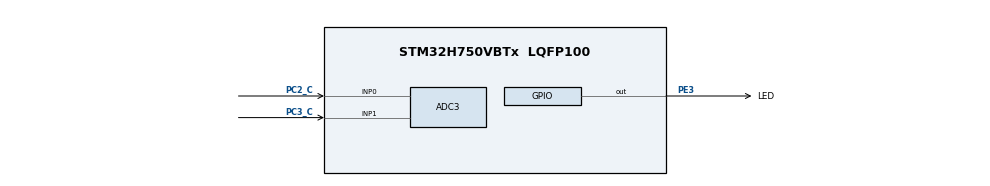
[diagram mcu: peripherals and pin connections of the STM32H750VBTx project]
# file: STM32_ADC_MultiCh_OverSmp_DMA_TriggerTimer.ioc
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ADC3.Channel-0\#ChannelRegularConversion=ADC_CHANNEL_VREFINT
ADC3.Channel-1\#ChannelRegularConversion=ADC_CHANNEL_0
ADC3.Channel-2\#ChannelRegularConversion=ADC_CHANNEL_1
ADC3.ContinuousConvMode=DISABLE
ADC3.ConversionDataManagement=ADC_CONVERSIONDATA_DMA_CIRCULAR
ADC3.EOCSelection=ADC_EOC_SEQ_CONV
ADC3.ExternalTrigConv=ADC_EXTERNALTRIG_T6_TRGO
ADC3.NbrOfConversion=3
ADC3.NbrOfConversionFlag=1
ADC3.OffsetNumber-0\#ChannelRegularConversion=ADC_OFFSET_NONE
ADC3.OffsetNumber-1\#ChannelRegularConversion=ADC_OFFSET_NONE
ADC3.OffsetNumber-2\#ChannelRegularConversion=ADC_OFFSET_NONE
ADC3.OffsetSignedSaturation-0\#ChannelRegularConversion=DISABLE
ADC3.OffsetSignedSaturation-1\#ChannelRegularConversion=DISABLE
ADC3.OffsetSignedSaturation-2\#ChannelRegularConversion=DISABLE
ADC3.Overrun=ADC_OVR_DATA_PRESERVED
ADC3.OversamplingMode=ENABLE
ADC3.Rank-0\#ChannelRegularConversion=1
ADC3.Rank-1\#ChannelRegularConversion=2
ADC3.Rank-2\#ChannelRegularConversion=3
ADC3.Ratio=1024
ADC3.RightBitShift=ADC_RIGHTBITSHIFT_10
ADC3.SamplingTime-0\#ChannelRegularConversion=ADC_SAMPLETIME_8CYCLES_5
ADC3.SamplingTime-1\#ChannelRegularConversion=ADC_SAMPLETIME_8CYCLES_5
ADC3.SamplingTime-2\#ChannelRegularConversion=ADC_SAMPLETIME_8CYCLES_5
CORTEX_M7.CPU_DCache=Enabled
CORTEX_M7.CPU_ICache=Enabled
Dma.ADC3.0.Direction=DMA_PERIPH_TO_MEMORY
Dma.ADC3.0.EventEnable=DISABLE
Dma.ADC3.0.FIFOMode=DMA_FIFOMODE_DISABLE
Dma.ADC3.0.Instance=DMA1_Stream0
Dma.ADC3.0.MemDataAlignment=DMA_MDATAALIGN_HALFWORD
Dma.ADC3.0.MemInc=DMA_MINC_ENABLE
Dma.ADC3.0.Mode=DMA_CIRCULAR
Dma.ADC3.0.PeriphDataAlignment=DMA_PDATAALIGN_HALFWORD
Dma.ADC3.0.PeriphInc=DMA_PINC_DISABLE
Dma.ADC3.0.Polarity=HAL_DMAMUX_REQ_GEN_RISING
Dma.ADC3.0.Priority=DMA_PRIORITY_LOW
Dma.ADC3.0.RequestNumber=1
Dma.ADC3.0.SignalID=NONE
Dma.ADC3.0.SyncEnable=DISABLE
Dma.ADC3.0.SyncPolarity=HAL_DMAMUX_SYNC_NO_EVENT
Dma.ADC3.0.SyncRequestNumber=1
Dma.ADC3.0.SyncSignalID=NONE
Dma.Request0=ADC3
Mcu.Family=STM32H7
Mcu.Name=STM32H750VBTx
Mcu.Package=LQFP100
NVIC.DMA1_Stream0_IRQn=true\:0\:0\:false\:false\:true\:false\:true
NVIC.PriorityGroup=NVIC_PRIORITYGROUP_4
PC2_C.Mode=IN0-Single-Ended
PC2_C.Signal=ADC3_INP0
PC3_C.Mode=IN1-Single-Ended
PC3_C.Signal=ADC3_INP1
PE3.GPIO_Label=LED
PE3.Signal=GPIO_Output
ProjectManager.HeapSize=0x200
ProjectManager.StackSize=0x400
ProjectManager.TargetToolchain=STM32CubeIDE
RCC.ADCFreq_Value=37500000
RCC.APB1Freq_Value=120000000
RCC.APB2Freq_Value=120000000
RCC.APB3Freq_Value=120000000
RCC.APB4Freq_Value=120000000
RCC.CortexFreq_Value=240000000
RCC.DIVM1=4
RCC.DIVM2=4
RCC.DIVN1=30
RCC.DIVN2=9
RCC.DIVP2=4
RCC.HCLKFreq_Value=120000000
RCC.HPRE=RCC_HCLK_DIV2
RCC.PLL2FRACN=3072
RCC.PLL3FRACN=0
RCC.PLLFRACN=0
RCC.PWR_Regulator_Voltage_Scale=PWR_REGULATOR_VOLTAGE_SCALE2
RCC.ProductRev=revV
RCC.SYSCLKFreq_VALUE=240000000
RCC.SYSCLKSource=RCC_SYSCLKSOURCE_PLLCLK
RCC.USBFreq_Value=240000000
TIM6.AutoReloadPreload=TIM_AUTORELOAD_PRELOAD_DISABLE
TIM6.Period=9999
TIM6.Prescaler=11999
TIM6.TIM_MasterOutputTrigger=TIM_TRGO_UPDATE
VP_ADC3_Vref_Input.Mode=IN-Vrefint
VP_TIM6_VS_ClockSourceINT.Mode=Enable_Timer
board=custom

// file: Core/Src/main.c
/* USER CODE BEGIN Header */
/**
  ******************************************************************************
  * @file           : main.c
  * @brief          : Main program body
  ******************************************************************************
  * @attention
  *
  * <h2><center>&copy; Copyright (c) 2021 STMicroelectronics.
  * All rights reserved.</center></h2>
  *
  * This software component is licensed by ST under BSD 3-Clause license,
  * the "License"; You may not use this file except in compliance with the
  * License. You may obtain a copy of the License at:
  *                        opensource.org/licenses/BSD-3-Clause
  *
  ******************************************************************************
  */
/* USER CODE END Header */
#include "main.h"

/* USER CODE BEGIN PD */
#define ChannelNo	3
/* USER CODE END PD */

ADC_HandleTypeDef hadc3;
DMA_HandleTypeDef hdma_adc3;

TIM_HandleTypeDef htim6;

/* USER CODE BEGIN PV */
uint16_t DMABuf[ChannelNo];
uint16_t VRefInt, ADC_INP0, ADC_INP1;
uint8_t DMA_Cplt = 0;
/* USER CODE END PV */

void SystemClock_Config(void);
static void MX_GPIO_Init(void);
static void MX_ADC3_Init(void);
static void MX_DMA_Init(void);
static void MX_TIM6_Init(void);

int main(void)
{

  /* Enable I-Cache---------------------------------------------------------*/
  SCB_EnableICache();

  /* Enable D-Cache---------------------------------------------------------*/
  SCB_EnableDCache();

  /* MCU Configuration--------------------------------------------------------*/

  /* Reset of all peripherals, Initializes the Flash interface and the Systick. */
  HAL_Init();

  /* Configure the system clock */
  SystemClock_Config();

  /* Initialize all configured peripherals */
  MX_GPIO_Init();
  MX_ADC3_Init();
  MX_DMA_Init();
  MX_TIM6_Init();
  /* USER CODE BEGIN 2 */
#ifdef LL_Driver
  LL_ADC_SetCommonPathInternalCh(__LL_ADC_COMMON_INSTANCE(ADC3),
		  LL_ADC_PATH_INTERNAL_VREFINT);
  LL_ADC_SetChannelPreSelection(ADC3, LL_ADC_CHANNEL_VREFINT);
  LL_ADC_SetChannelPreSelection(ADC3, LL_ADC_CHANNEL_0);
  LL_ADC_SetChannelPreSelection(ADC3, LL_ADC_CHANNEL_1);
  LL_ADC_REG_SetDataTransferMode(ADC3, LL_ADC_REG_DMA_TRANSFER_UNLIMITED);

  LL_ADC_StartCalibration(ADC3, LL_ADC_CALIB_OFFSET, LL_ADC_SINGLE_ENDED);
  while( LL_ADC_IsCalibrationOnGoing(ADC3));

  LL_TIM_EnableCounter(TIM6);

  LL_DMA_ConfigAddresses(DMA1, LL_DMA_STREAM_0,
		  LL_ADC_DMA_GetRegAddr(ADC3, LL_ADC_DMA_REG_REGULAR_DATA),
		  (uint32_t)&DMABuf, LL_DMA_DIRECTION_PERIPH_TO_MEMORY);
  LL_DMA_SetDataLength(DMA1, LL_DMA_STREAM_0, ChannelNo);
  LL_DMA_EnableIT_TC(DMA1, LL_DMA_STREAM_0);
  LL_DMA_EnableStream(DMA1, LL_DMA_STREAM_0);

  LL_ADC_Enable(ADC3);
  while(LL_ADC_IsActiveFlag_ADRDY(ADC3) != SET);
  LL_ADC_REG_StartConversion(ADC3);
#else
  if (HAL_ADCEx_Calibration_Start(&hadc3, ADC_CALIB_OFFSET, ADC_SINGLE_ENDED)
		  != HAL_OK)
  {
	  return HAL_ERROR;
  }

  if (HAL_TIM_Base_Start(&htim6) != HAL_OK)
  {
	  return HAL_ERROR;
  }

  if (HAL_ADC_Start_DMA(&hadc3, (uint32_t*)DMABuf, ChannelNo) != HAL_OK)
  {
	  return HAL_ERROR;
  }
#endif
  /* USER CODE END 2 */

  /* Infinite loop */
  while (1)
  {

    /* USER CODE BEGIN 3 */
	  if (DMA_Cplt == 1)
	  {
#ifdef LL_Driver
		  VRefInt	= __LL_ADC_CALC_VREFANALOG_VOLTAGE(DMABuf[0],
				  LL_ADC_GetResolution(ADC3));
		  ADC_INP0 	= __LL_ADC_CALC_DATA_TO_VOLTAGE(VRefInt, DMABuf[1],
				  LL_ADC_GetResolution(ADC3));
		  ADC_INP1 	= __LL_ADC_CALC_DATA_TO_VOLTAGE(VRefInt, DMABuf[2],
				  LL_ADC_GetResolution(ADC3));
#else
		  VRefInt	= __HAL_ADC_CALC_VREFANALOG_VOLTAGE(DMABuf[0],
				  hadc3.Init.Resolution);
		  ADC_INP0 	= __HAL_ADC_CALC_DATA_TO_VOLTAGE(VRefInt, DMABuf[1],
				  hadc3.Init.Resolution);
		  ADC_INP1 	= __HAL_ADC_CALC_DATA_TO_VOLTAGE(VRefInt, DMABuf[2],
				  hadc3.Init.Resolution);
#endif
		  DMA_Cplt	= 0;
	  }
  }
  /* USER CODE END 3 */
}

void SystemClock_Config(void)
{
  RCC_OscInitTypeDef RCC_OscInitStruct = {0};
  RCC_ClkInitTypeDef RCC_ClkInitStruct = {0};

  /** Supply configuration update enable
  */
  HAL_PWREx_ConfigSupply(PWR_LDO_SUPPLY);
  /** Configure the main internal regulator output voltage
  */
  __HAL_PWR_VOLTAGESCALING_CONFIG(PWR_REGULATOR_VOLTAGE_SCALE2);

  while(!__HAL_PWR_GET_FLAG(PWR_FLAG_VOSRDY)) {}
  /** Macro to configure the PLL clock source
  */
  __HAL_RCC_PLL_PLLSOURCE_CONFIG(RCC_PLLSOURCE_HSI);
  /** Initializes the RCC Oscillators according to the specified parameters
  * in the RCC_OscInitTypeDef structure.
  */
  RCC_OscInitStruct.OscillatorType = RCC_OSCILLATORTYPE_HSI;
  RCC_OscInitStruct.HSIState = RCC_HSI_DIV1;
  RCC_OscInitStruct.HSICalibrationValue = RCC_HSICALIBRATION_DEFAULT;
  RCC_OscInitStruct.PLL.PLLState = RCC_PLL_ON;
  RCC_OscInitStruct.PLL.PLLSource = RCC_PLLSOURCE_HSI;
  RCC_OscInitStruct.PLL.PLLM = 4;
  RCC_OscInitStruct.PLL.PLLN = 30;
  RCC_OscInitStruct.PLL.PLLP = 2;
  RCC_OscInitStruct.PLL.PLLQ = 2;
  RCC_OscInitStruct.PLL.PLLR = 2;
  RCC_OscInitStruct.PLL.PLLRGE = RCC_PLL1VCIRANGE_3;
  RCC_OscInitStruct.PLL.PLLVCOSEL = RCC_PLL1VCOWIDE;
  RCC_OscInitStruct.PLL.PLLFRACN = 0;
  if (HAL_RCC_OscConfig(&RCC_OscInitStruct) != HAL_OK)
  {
    Error_Handler();
  }
  /** Initializes the CPU, AHB and APB buses clocks
  */
  RCC_ClkInitStruct.ClockType = RCC_CLOCKTYPE_HCLK|RCC_CLOCKTYPE_SYSCLK
                              |RCC_CLOCKTYPE_PCLK1|RCC_CLOCKTYPE_PCLK2
                              |RCC_CLOCKTYPE_D3PCLK1|RCC_CLOCKTYPE_D1PCLK1;
  RCC_ClkInitStruct.SYSCLKSource = RCC_SYSCLKSOURCE_PLLCLK;
  RCC_ClkInitStruct.SYSCLKDivider = RCC_SYSCLK_DIV1;
  RCC_ClkInitStruct.AHBCLKDivider = RCC_HCLK_DIV2;
  RCC_ClkInitStruct.APB3CLKDivider = RCC_APB3_DIV1;
  RCC_ClkInitStruct.APB1CLKDivider = RCC_APB1_DIV1;
  RCC_ClkInitStruct.APB2CLKDivider = RCC_APB2_DIV1;
  RCC_ClkInitStruct.APB4CLKDivider = RCC_APB4_DIV1;

  if (HAL_RCC_ClockConfig(&RCC_ClkInitStruct, FLASH_LATENCY_2) != HAL_OK)
  {
    Error_Handler();
  }
}

static void MX_ADC3_Init(void)
{

  ADC_ChannelConfTypeDef sConfig = {0};

  /** Common config
  */
  hadc3.Instance = ADC3;
  hadc3.Init.ClockPrescaler = ADC_CLOCK_ASYNC_DIV2;
  hadc3.Init.Resolution = ADC_RESOLUTION_16B;
  hadc3.Init.ScanConvMode = ADC_SCAN_ENABLE;
  hadc3.Init.EOCSelection = ADC_EOC_SEQ_CONV;
  hadc3.Init.LowPowerAutoWait = DISABLE;
  hadc3.Init.ContinuousConvMode = DISABLE;
  hadc3.Init.NbrOfConversion = 3;
  hadc3.Init.DiscontinuousConvMode = DISABLE;
  hadc3.Init.ExternalTrigConv = ADC_EXTERNALTRIG_T6_TRGO;
  hadc3.Init.ExternalTrigConvEdge = ADC_EXTERNALTRIGCONVEDGE_RISING;
  hadc3.Init.ConversionDataManagement = ADC_CONVERSIONDATA_DMA_CIRCULAR;
  hadc3.Init.Overrun = ADC_OVR_DATA_PRESERVED;
  hadc3.Init.LeftBitShift = ADC_LEFTBITSHIFT_NONE;
  hadc3.Init.OversamplingMode = ENABLE;
  hadc3.Init.Oversampling.Ratio = 1024;
  hadc3.Init.Oversampling.RightBitShift = ADC_RIGHTBITSHIFT_10;
  hadc3.Init.Oversampling.TriggeredMode = ADC_TRIGGEREDMODE_SINGLE_TRIGGER;
  hadc3.Init.Oversampling.OversamplingStopReset = ADC_REGOVERSAMPLING_CONTINUED_MODE;
  if (HAL_ADC_Init(&hadc3) != HAL_OK)
  {
    Error_Handler();
  }
  /** Configure Regular Channel
  */
  sConfig.Channel = ADC_CHANNEL_VREFINT;
  sConfig.Rank = ADC_REGULAR_RANK_1;
  sConfig.SamplingTime = ADC_SAMPLETIME_8CYCLES_5;
  sConfig.SingleDiff = ADC_SINGLE_ENDED;
  sConfig.OffsetNumber = ADC_OFFSET_NONE;
  sConfig.Offset = 0;
  sConfig.OffsetSignedSaturation = DISABLE;
  if (HAL_ADC_ConfigChannel(&hadc3, &sConfig) != HAL_OK)
  {
    Error_Handler();
  }
  /** Configure Regular Channel
  */
  sConfig.Channel = ADC_CHANNEL_0;
  sConfig.Rank = ADC_REGULAR_RANK_2;
  if (HAL_ADC_ConfigChannel(&hadc3, &sConfig) != HAL_OK)
  {
    Error_Handler();
  }
  /** Configure Regular Channel
  */
  sConfig.Channel = ADC_CHANNEL_1;
  sConfig.Rank = ADC_REGULAR_RANK_3;
  if (HAL_ADC_ConfigChannel(&hadc3, &sConfig) != HAL_OK)
  {
    Error_Handler();
  }

}

static void MX_TIM6_Init(void)
{

  TIM_MasterConfigTypeDef sMasterConfig = {0};

  htim6.Instance = TIM6;
  htim6.Init.Prescaler = 11999;
  htim6.Init.CounterMode = TIM_COUNTERMODE_UP;
  htim6.Init.Period = 9999;
  htim6.Init.AutoReloadPreload = TIM_AUTORELOAD_PRELOAD_DISABLE;
  if (HAL_TIM_Base_Init(&htim6) != HAL_OK)
  {
    Error_Handler();
  }
  sMasterConfig.MasterOutputTrigger = TIM_TRGO_UPDATE;
  sMasterConfig.MasterSlaveMode = TIM_MASTERSLAVEMODE_DISABLE;
  if (HAL_TIMEx_MasterConfigSynchronization(&htim6, &sMasterConfig) != HAL_OK)
  {
    Error_Handler();
  }

}

static void MX_DMA_Init(void)
{

  /* DMA controller clock enable */
  __HAL_RCC_DMA1_CLK_ENABLE();

  /* DMA interrupt init */
  /* DMA1_Stream0_IRQn interrupt configuration */
  HAL_NVIC_SetPriority(DMA1_Stream0_IRQn, 0, 0);
  HAL_NVIC_EnableIRQ(DMA1_Stream0_IRQn);

}

static void MX_GPIO_Init(void)
{
  GPIO_InitTypeDef GPIO_InitStruct = {0};

  /* GPIO Ports Clock Enable */
  __HAL_RCC_GPIOE_CLK_ENABLE();
  __HAL_RCC_GPIOC_CLK_ENABLE();

  /*Configure GPIO pin Output Level */
  HAL_GPIO_WritePin(LED_GPIO_Port, LED_Pin, GPIO_PIN_RESET);

  /*Configure GPIO pin : LED_Pin */
  GPIO_InitStruct.Pin = LED_Pin;
  GPIO_InitStruct.Mode = GPIO_MODE_OUTPUT_PP;
  GPIO_InitStruct.Pull = GPIO_NOPULL;
  GPIO_InitStruct.Speed = GPIO_SPEED_FREQ_LOW;
  HAL_GPIO_Init(LED_GPIO_Port, &GPIO_InitStruct);

}

/* USER CODE BEGIN 4 */
#ifdef LL_Driver
void ADC_DMA_Callback(void)
{
	LL_GPIO_TogglePin(LED_GPIO_Port, LED_Pin);
	SCB_InvalidateDCache_by_Addr((uint32_t*)DMABuf, ChannelNo);
	DMA_Cplt = 1;
}
#else
void HAL_ADC_ConvCpltCallback(ADC_HandleTypeDef* hadc)
{
	SCB_InvalidateDCache_by_Addr((uint32_t*)DMABuf, ChannelNo);
	HAL_GPIO_TogglePin(LED_GPIO_Port, LED_Pin);
	DMA_Cplt = 1;
}
#endif
/* USER CODE END 4 */

void Error_Handler(void)
{
  __disable_irq();
  while (1)
  {
  }
}

/************************ (C) COPYRIGHT STMicroelectronics *****END OF FILE****/
